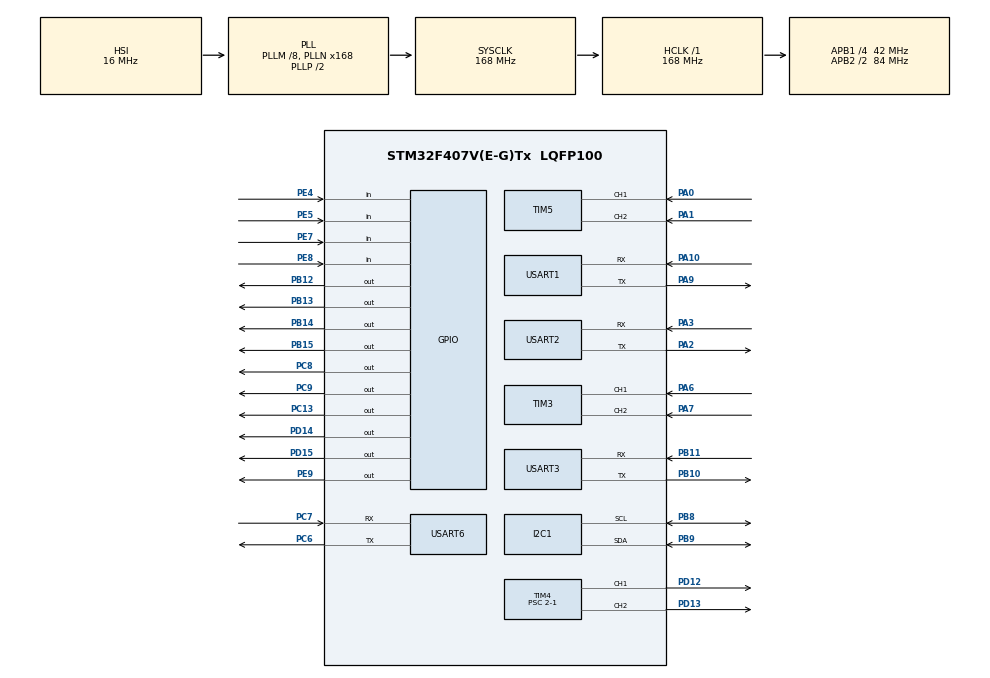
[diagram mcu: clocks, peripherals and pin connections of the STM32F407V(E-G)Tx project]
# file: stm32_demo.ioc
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Dma.Request0=USART3_RX
Dma.Request1=USART6_RX
Dma.USART3_RX.0.Direction=DMA_PERIPH_TO_MEMORY
Dma.USART3_RX.0.FIFOMode=DMA_FIFOMODE_DISABLE
Dma.USART3_RX.0.Instance=DMA1_Stream1
Dma.USART3_RX.0.MemDataAlignment=DMA_MDATAALIGN_BYTE
Dma.USART3_RX.0.MemInc=DMA_MINC_ENABLE
Dma.USART3_RX.0.Mode=DMA_NORMAL
Dma.USART3_RX.0.PeriphDataAlignment=DMA_PDATAALIGN_BYTE
Dma.USART3_RX.0.PeriphInc=DMA_PINC_DISABLE
Dma.USART3_RX.0.Priority=DMA_PRIORITY_LOW
Dma.USART6_RX.1.Direction=DMA_PERIPH_TO_MEMORY
Dma.USART6_RX.1.FIFOMode=DMA_FIFOMODE_DISABLE
Dma.USART6_RX.1.Instance=DMA2_Stream1
Dma.USART6_RX.1.MemDataAlignment=DMA_MDATAALIGN_BYTE
Dma.USART6_RX.1.MemInc=DMA_MINC_ENABLE
Dma.USART6_RX.1.Mode=DMA_NORMAL
Dma.USART6_RX.1.PeriphDataAlignment=DMA_PDATAALIGN_BYTE
Dma.USART6_RX.1.PeriphInc=DMA_PINC_DISABLE
Dma.USART6_RX.1.Priority=DMA_PRIORITY_LOW
Mcu.Family=STM32F4
Mcu.Name=STM32F407V(E-G)Tx
Mcu.Package=LQFP100
NVIC.DMA1_Stream1_IRQn=true\:0\:0\:false\:false\:true\:false\:true\:true
NVIC.DMA2_Stream1_IRQn=true\:0\:0\:false\:false\:true\:false\:true\:true
NVIC.PriorityGroup=NVIC_PRIORITYGROUP_4
NVIC.TIM8_TRG_COM_TIM14_IRQn=true\:0\:0\:false\:false\:true\:true\:true\:true
NVIC.TIM8_UP_TIM13_IRQn=true\:0\:0\:false\:false\:true\:true\:true\:true
NVIC.USART2_IRQn=true\:0\:0\:false\:false\:true\:true\:true\:true
NVIC.USART3_IRQn=true\:0\:0\:false\:false\:true\:true\:true\:true
PA0-WKUP.Signal=S_TIM5_CH1
PA1.Signal=S_TIM5_CH2
PA10.Mode=Asynchronous
PA10.Signal=USART1_RX
PA13.Mode=Serial_Wire
PA13.Signal=SYS_JTMS-SWDIO
PA14.Mode=Serial_Wire
PA14.Signal=SYS_JTCK-SWCLK
PA2.Mode=Asynchronous
PA2.Signal=USART2_TX
PA3.Mode=Asynchronous
PA3.Signal=USART2_RX
PA6.Signal=S_TIM3_CH1
PA7.Signal=S_TIM3_CH2
PA9.Mode=Asynchronous
PA9.Signal=USART1_TX
PB10.Mode=Asynchronous
PB10.Signal=USART3_TX
PB11.Mode=Asynchronous
PB11.Signal=USART3_RX
PB12.Signal=GPIO_Output
PB13.Signal=GPIO_Output
PB14.Signal=GPIO_Output
PB15.Signal=GPIO_Output
PB8.Mode=I2C
PB8.Signal=I2C1_SCL
PB9.Mode=I2C
PB9.Signal=I2C1_SDA
PC13-ANTI_TAMP.Signal=GPIO_Output
PC14-OSC32_IN.Mode=LSE-External-Oscillator
PC14-OSC32_IN.Signal=RCC_OSC32_IN
PC15-OSC32_OUT.Mode=LSE-External-Oscillator
PC15-OSC32_OUT.Signal=RCC_OSC32_OUT
PC6.Mode=Asynchronous
PC6.Signal=USART6_TX
PC7.Mode=Asynchronous
PC7.Signal=USART6_RX
PC8.Signal=GPIO_Output
PC9.Signal=GPIO_Output
PD12.Signal=S_TIM4_CH1
PD13.Signal=S_TIM4_CH2
PD14.Signal=GPIO_Output
PD15.Signal=GPIO_Output
PE4.Signal=GPIO_Input
PE5.Signal=GPIO_Input
PE7.Signal=GPIO_Input
PE8.Signal=GPIO_Input
PE9.Signal=GPIO_Output
PH0-OSC_IN.Mode=HSE-External-Oscillator
PH0-OSC_IN.Signal=RCC_OSC_IN
PH1-OSC_OUT.Mode=HSE-External-Oscillator
PH1-OSC_OUT.Signal=RCC_OSC_OUT
ProjectManager.HeapSize=0x200
ProjectManager.StackSize=0x400
ProjectManager.TargetToolchain=MDK-ARM V5.32
RCC.48MHZClocksFreq_Value=84000000
RCC.AHBFreq_Value=168000000
RCC.APB1CLKDivider=RCC_HCLK_DIV4
RCC.APB1Freq_Value=42000000
RCC.APB1TimFreq_Value=84000000
RCC.APB2CLKDivider=RCC_HCLK_DIV2
RCC.APB2Freq_Value=84000000
RCC.APB2TimFreq_Value=168000000
RCC.CortexFreq_Value=168000000
RCC.HCLKFreq_Value=168000000
RCC.HSE_VALUE=25000000
RCC.HSI_VALUE=16000000
RCC.PLLM=8
RCC.PLLN=168
RCC.SYSCLKFreq_VALUE=168000000
RCC.SYSCLKSource=RCC_SYSCLKSOURCE_PLLCLK
RCC.VCOOutputFreq_Value=336000000
SH.S_TIM3_CH1.0=TIM3_CH1,Encoder_Interface
SH.S_TIM3_CH2.0=TIM3_CH2,Encoder_Interface
SH.S_TIM4_CH1.0=TIM4_CH1,PWM Generation1 CH1
SH.S_TIM4_CH2.0=TIM4_CH2,PWM Generation2 CH2
SH.S_TIM5_CH1.0=TIM5_CH1,Encoder_Interface
SH.S_TIM5_CH2.0=TIM5_CH2,Encoder_Interface
TIM13.AutoReloadPreload=TIM_AUTORELOAD_PRELOAD_ENABLE
TIM13.Period=99
TIM13.Prescaler=8399
TIM14.AutoReloadPreload=TIM_AUTORELOAD_PRELOAD_ENABLE
TIM14.Period=49999
TIM14.Prescaler=84-1
TIM3.EncoderMode=TIM_ENCODERMODE_TI12
TIM3.IC1Filter=10
TIM4.AutoReloadPreload=TIM_AUTORELOAD_PRELOAD_ENABLE
TIM4.Channel-PWM\ Generation1\ CH1=TIM_CHANNEL_1
TIM4.Channel-PWM\ Generation2\ CH2=TIM_CHANNEL_2
TIM4.Period=4200-1
TIM4.Prescaler=2-1
TIM5.EncoderMode=TIM_ENCODERMODE_TI12
USART1.VirtualMode=VM_ASYNC
USART2.VirtualMode=VM_ASYNC
USART3.VirtualMode=VM_ASYNC
USART6.VirtualMode=VM_ASYNC
VP_TIM13_VS_ClockSourceINT.Mode=Enable_Timer
VP_TIM14_VS_ClockSourceINT.Mode=Enable_Timer
VP_TIM4_VS_ClockSourceINT.Mode=Internal
board=custom

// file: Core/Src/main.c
/* USER CODE BEGIN Header */
/**
  ******************************************************************************
  * @file           : main.c
  * @brief          : Main program body
  ******************************************************************************
  * @attention
  *
  * Copyright (c) 2026 STMicroelectronics.
  * All rights reserved.
  *
  * This software is licensed under terms that can be found in the LICENSE file
  * in the root directory of this software component.
  * If no LICENSE file comes with this software, it is provided AS-IS.
  *
  ******************************************************************************
  */
/* USER CODE END Header */
#include "main.h"
#include "dma.h"
#include "i2c.h"
#include "tim.h"
#include "usart.h"
#include "gpio.h"

void SystemClock_Config(void);

int main(void)
{

  /* MCU Configuration--------------------------------------------------------*/

  /* Reset of all peripherals, Initializes the Flash interface and the Systick. */
  HAL_Init();

  /* Configure the system clock */
  SystemClock_Config();

  /* Initialize all configured peripherals */
  MX_GPIO_Init();
  MX_DMA_Init();
  MX_TIM4_Init();
  MX_TIM5_Init();
  MX_TIM3_Init();
  MX_TIM14_Init();
  MX_USART1_UART_Init();
  MX_USART2_UART_Init();
  MX_USART3_UART_Init();
  MX_USART6_UART_Init();
  MX_I2C1_Init();
  MX_TIM13_Init();
  /* USER CODE BEGIN 2 */
	Core_Main_Init();
  /* USER CODE END 2 */

  /* Infinite loop */
  while (1)
  {

    /* USER CODE BEGIN 3 */
		Core_Main_Master();
  }
  /* USER CODE END 3 */
}

void SystemClock_Config(void)
{
  RCC_OscInitTypeDef RCC_OscInitStruct = {0};
  RCC_ClkInitTypeDef RCC_ClkInitStruct = {0};

  /** Configure the main internal regulator output voltage
  */
  __HAL_RCC_PWR_CLK_ENABLE();
  __HAL_PWR_VOLTAGESCALING_CONFIG(PWR_REGULATOR_VOLTAGE_SCALE1);

  /** Initializes the RCC Oscillators according to the specified parameters
  * in the RCC_OscInitTypeDef structure.
  */
  RCC_OscInitStruct.OscillatorType = RCC_OSCILLATORTYPE_HSI;
  RCC_OscInitStruct.HSIState = RCC_HSI_ON;
  RCC_OscInitStruct.HSICalibrationValue = RCC_HSICALIBRATION_DEFAULT;
  RCC_OscInitStruct.PLL.PLLState = RCC_PLL_ON;
  RCC_OscInitStruct.PLL.PLLSource = RCC_PLLSOURCE_HSI;
  RCC_OscInitStruct.PLL.PLLM = 8;
  RCC_OscInitStruct.PLL.PLLN = 168;
  RCC_OscInitStruct.PLL.PLLP = RCC_PLLP_DIV2;
  RCC_OscInitStruct.PLL.PLLQ = 4;
  if (HAL_RCC_OscConfig(&RCC_OscInitStruct) != HAL_OK)
  {
    Error_Handler();
  }

  /** Initializes the CPU, AHB and APB buses clocks
  */
  RCC_ClkInitStruct.ClockType = RCC_CLOCKTYPE_HCLK|RCC_CLOCKTYPE_SYSCLK
                              |RCC_CLOCKTYPE_PCLK1|RCC_CLOCKTYPE_PCLK2;
  RCC_ClkInitStruct.SYSCLKSource = RCC_SYSCLKSOURCE_PLLCLK;
  RCC_ClkInitStruct.AHBCLKDivider = RCC_SYSCLK_DIV1;
  RCC_ClkInitStruct.APB1CLKDivider = RCC_HCLK_DIV4;
  RCC_ClkInitStruct.APB2CLKDivider = RCC_HCLK_DIV2;

  if (HAL_RCC_ClockConfig(&RCC_ClkInitStruct, FLASH_LATENCY_5) != HAL_OK)
  {
    Error_Handler();
  }
}

void Error_Handler(void)
{
  __disable_irq();
  while (1)
  {
  }
}
